# Baikal-U register map
Vendor: BAIKAL ELECTRONICS, JSC; File version: 1.0
Baikal Baikal-U SVD (System View Description)
CPU: RISC-V r0p0, little endian, no MPU, no FPU, 3 interrupt priority bits
Registers are 32-bit, read-write, reset 0x0 unless marked. A register's access mark holds for its fields unless they carry their own. Offsets are from the block's base; lines under a group give offsets from that group; [hi:lo] are bit positions; {n}, {i} and the like mark numbered series; 'fields as' and 'values as' point back to an identical list; <NAME> marks a mode.

## Memory map
0x11000000 QSPI size 0x1000 — Quad Serial Peripheral Interface
0x11001000 UART size 0x1000 — Universal Asynchronous Receiver/Transmitter
0x11002000 UART1 size 0x1000
0x11003000 UART2 size 0x1000
0x11004000 I2C size 0x1000 — Inter Integrated Circuit Interface
0x11005000 I2C1 size 0x1000
0x11006000 I2S size 0x1000 — Inter Integrated Circuit Sound Interface
0x11007000 TIM size 0x1000 — Timer
0x11008000 WDT size 0x1000 — WatchDog Timer (WDT)
0x11009000 GPIO size 0x1000 — General Purpose I/O
0x1100A000 PWMG size 0x1000 — General Purpose Timer
0x1100B000 SPI size 0x1000 — Serial Peripheral Interface (SPI)
0x1100C000 SPI1 size 0x1000
0x11010000 CANFD size 0x1000 — Controller Area Network
0x13000000 QSPI1 size 0x1000
0x13001000 UART3 size 0x1000
0x13002000 UART4 size 0x1000
0x13003000 UART5 size 0x1000
0x13004000 I2C2 size 0x1000
0x13005000 I2C3 size 0x1000
0x13006000 I2S1 size 0x1000
0x13007000 TIM1 size 0x1000
0x13008000 WDT1 size 0x1000
0x13009000 GPIO1 size 0x1000
0x1300A000 PWMG1 size 0x1000
0x1300B000 SPI2 size 0x1000
0x1300C000 SPI3 size 0x1000
0x13010000 CANFD1 size 0x1000
0x14000000 CRU size 0x1000 — Control Registers Unit
0x14001000 ADC size 0x1000 — Analog to Digital Converter
0x14002000 ADC1 size 0x1000
0x14003000 ADC2 size 0x1000
0x14004000 PWMA size 0x1000 — Advanced-control Timer
0x14004050 QE size 0x1000 — Quadrature Encoder
0x14005000 PWMA1 size 0x1000
0x14005050 QE1 size 0x1000
0x14006000 PWMA2 size 0x1000
0x14006050 QE2 size 0x1000
0x14007000 PWMA3 size 0x1000
0x14007050 QE3 size 0x1000
0x14008000 GPIO2 size 0x1000
0x14009000 UART6 size 0x1000
0x1400A000 UART7 size 0x1000
0x1400B000 AXI size 0x1000 — Advanced eXtensible Interface
0x15000000 USB size 0x1000
0x15100000 DMA size 0x1000 — Direct Memory Access Controller
0x15101000 DMA1 size 0x1000
0x15102000 DMA2 size 0x1000
0x151037F0 CORE2_INT size 0x1000 — CORE2 subsystem, INT
0x151037F4 CORE2_PIO size 0x1000 — CORE2 subsystem, PIO
0x15108000 AHB size 0x1000 — Advanced High-performance Bus
0xA0060000 EFLASH size 0x1000 — Embedded Flash

## ADC — Analog to Digital Converter
Base 0x14001000
Same registers: ADC1 0x14002000, ADC2 0x14003000
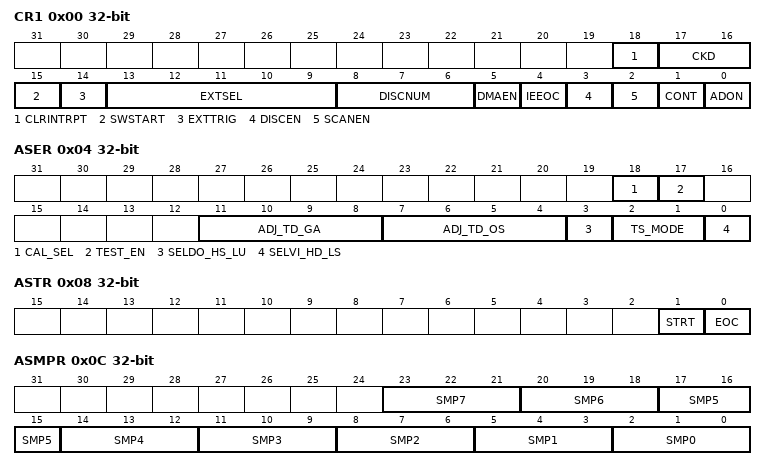
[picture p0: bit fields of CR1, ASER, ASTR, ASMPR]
0x00 CR1 — Control register 1
  [18] CLRINTRPT — Clear interrupt
    0=DISABLE; 1=ENABLE
  [17:16] CKD — Clock division
    0=DIV8 (CK_INT divided by 8); 1=DIV4 (CK_INT divided by 4); 2=DIV2 (CK_INT divided by 2)
  [15] SWSTART — Start of conversion
    0=DISABLE; 1=ENABLE
  [14] EXTTRIG — External trigger conversion mode enable
    0=DISABLE; 1=ENABLE
  [13:9] EXTSEL — External event select
    {v}=External event {v} (v=0..19)
  [8:6] DISCNUM — Discontinuous mode channel count
    0=1RANK; {v}={v+1}RANKS (v=1..7)
  [5] DMAEN — DMA enable
    0=DISABLE (DMA transfer is disabled); 1=ENABLE (DMA transfer is enabled)
  [4] IEEOC — EOC interrupt enable
    0=DISABLE; 1=ENABLE
  [3] DISCEN — Discontinuous mode enable
    0=DISABLE (Discontinuous mode is disabled); 1=ENABLE (Discontinuous mode is enabled)
  [2] SCANEN — Scan mode enable
    0=DISABLE (Scan mode is disabled); 1=ENABLE (Scan mode is enabled)
  [1] CONT — Continuous conversion enable
    0=DISABLE (Continuous conversion is disabled); 1=ENABLE (Continuous conversion is enabled)
  [0] ADON — ADC on/off
    0=DISABLE; 1=ENABLE
0x04 ASER — Set register
  [18] CAL_SEL — Calibration mode enable
    0=DISABLE; 1=ENABLE
  [17] TEST_EN — Test mode enable
    0=DISABLE; 1=ENABLE
  [11:8] ADJ_TD_GA — Temperature sensor gain adjustment signal
  [7:4] ADJ_TD_OS — Temperature sensor offset adjustment signal
  [3] SELDO_HS_LU — Output data type selection
    0=UNSIGNED (Unsigned data); 1=SIGNED (Signed data)
  [2:1] TS_MODE — Filter mode of the temperature sensor
    0=BYPASS (Bypass internal lowpass filter); 1=AVG64 (64 times average); 2=AVG128 (128 times average); 3=AVG256 (256 times average)
  [0] SELVI_HD_LS — Input type selection
    0=SINGLE (Single end); 1=DIFF (Differential)
0x08 ASTR — Status register
  [1] STRT — Start of conversion
    0=DISABLE; 1=ENABLE
  [0] EOC — End of conversion
    0=DISABLE; 1=ENABLE
0x0C ASMPR — Sample time register
  [3n+2:3n] SMP{n} (n=1..7) — Sample count {n}
    0=3 periods; 1=25 periods; 2=50 periods; 3=100 periods; 4=150 periods; 5=180 periods; 6=250 periods; 7=300 periods
  [2:0] SMP0 — Sample count 0
    0=3CYCLES; 1=25CYCLES; 2=50CYCLES; 3=100CYCLES; 4=150CYCLES; 5=180CYCLES; 6=250CYCLES; 7=300CYCLES
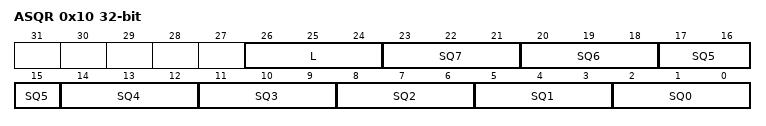
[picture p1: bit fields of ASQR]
0x10 ASQR — Sequence register
  [26:24] L — The length of the sequence
    0=1RANK; {v}={v+1}RANKS (v=1..7)
  [3n+2:3n] SQ{n} (n=0..7) — Channel {n}
0x14 ADR — Data register
  [11:0] ADR — ADC data
